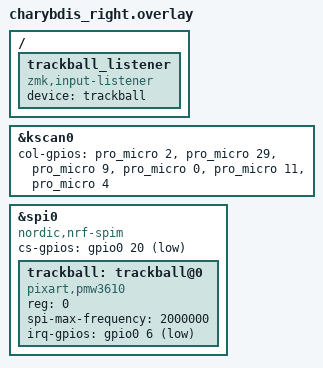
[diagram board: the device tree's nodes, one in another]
/*
 * Copyright (c) 2020 ZMK Contributors
 *
 * SPDX-License-Identifier: MIT
 */

#include "charybdis.dtsi"

&kscan0 {
	col-gpios
		= <&pro_micro 2 (GPIO_ACTIVE_HIGH | GPIO_PULL_DOWN)>
		, <&pro_micro 29 (GPIO_ACTIVE_HIGH | GPIO_PULL_DOWN)>
		, <&pro_micro 9 (GPIO_ACTIVE_HIGH | GPIO_PULL_DOWN)>
		, <&pro_micro 0  (GPIO_ACTIVE_HIGH | GPIO_PULL_DOWN)>
		, <&pro_micro 11 (GPIO_ACTIVE_HIGH | GPIO_PULL_DOWN)>
		, <&pro_micro 4  (GPIO_ACTIVE_HIGH | GPIO_PULL_DOWN)>
		;
};

// trackball bus

&spi0 {
    status = "okay";
    compatible = "nordic,nrf-spim";
    cs-gpios = <&gpio0 20 GPIO_ACTIVE_LOW>;

    trackball: trackball@0 {
        status = "okay";
        compatible = "pixart,pmw3610";
        reg = <0>;
        spi-max-frequency = <2000000>;
        irq-gpios = <&gpio0 6 (GPIO_ACTIVE_LOW | GPIO_PULL_UP)>;
        //scroll-layers = <1>;
        //snipe-layers = <2>;
      // automouse-layer = <3>;
    };
};
/ {
    trackball_listener {
        compatible = "zmk,input-listener";
        device = <&trackball>;
    };
};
